# j7am_pulsar1_mem_cbass0_QOS register map
Vendor: Texas Instruments
Peripheral module from a debugger description file (folder J721S2).
Registers are 32-bit, read-write, reset 0x7000 unless marked. A register's access mark holds for its fields unless they carry their own. Offsets are as the file gives them; lines under a group give offsets from that group; [hi:lo] are bit positions; {n}, {i} and the like mark numbered series; 'fields as' and 'values as' point back to an identical list; <NAME> marks a mode.

## j7am_pulsar1_mem_cbass0_QOS
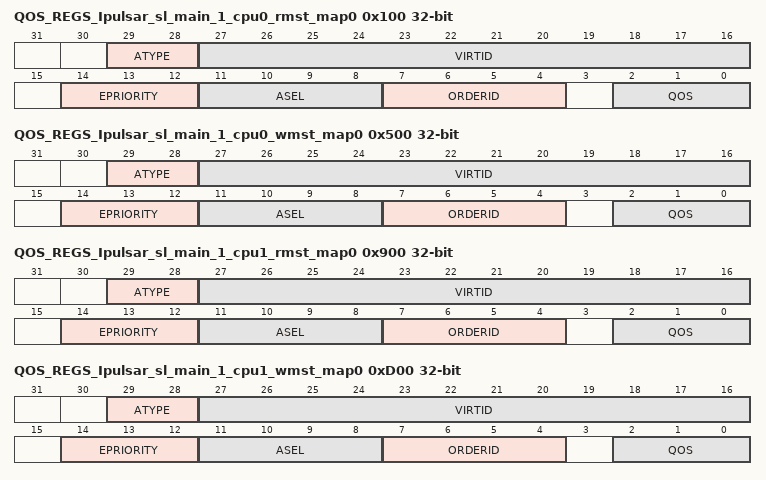
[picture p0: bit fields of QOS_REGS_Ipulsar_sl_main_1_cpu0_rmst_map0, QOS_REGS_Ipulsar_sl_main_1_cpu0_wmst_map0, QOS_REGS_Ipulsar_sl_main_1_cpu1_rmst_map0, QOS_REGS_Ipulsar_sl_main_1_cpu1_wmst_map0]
0x100 QOS_REGS_Ipulsar_sl_main_1_cpu0_rmst_map0 — The Map Register defines the fields for the master Ipulsar_sl_main_1.cpu0_rmst per channel.
  [29:28] ATYPE — epriority signal for channel N. 0 = physical. 1 = intermediate. 2 = virtual. 3 = physical with coherence.
  [27:16] VIRTID — virtid signal for channel N.
  [14:12] EPRIORITY — epriority signal for channel N.
  [11:8] ASEL — asel signal for channel N. 0 = SOC address. 1-15 = peripheral address.
  [7:4] ORDERID — orderid signal for channel N.
  [2:0] QOS — qos signal for channel N.
0x500 QOS_REGS_Ipulsar_sl_main_1_cpu0_wmst_map0 — The Map Register defines the fields for the master Ipulsar_sl_main_1.cpu0_wmst per channel.
  fields as QOS_REGS_Ipulsar_sl_main_1_cpu0_rmst_map0
0x900 QOS_REGS_Ipulsar_sl_main_1_cpu1_rmst_map0 — The Map Register defines the fields for the master Ipulsar_sl_main_1.cpu1_rmst per channel.
  fields as QOS_REGS_Ipulsar_sl_main_1_cpu0_rmst_map0
0xD00 QOS_REGS_Ipulsar_sl_main_1_cpu1_wmst_map0 — The Map Register defines the fields for the master Ipulsar_sl_main_1.cpu1_wmst per channel.
  fields as QOS_REGS_Ipulsar_sl_main_1_cpu0_rmst_map0
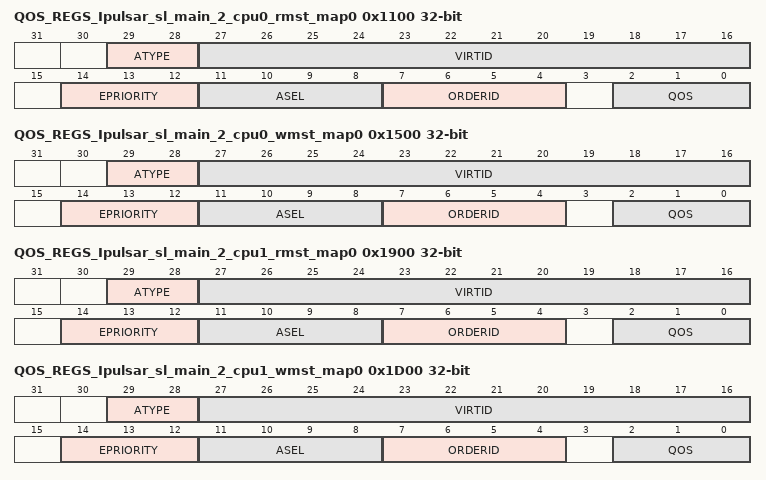
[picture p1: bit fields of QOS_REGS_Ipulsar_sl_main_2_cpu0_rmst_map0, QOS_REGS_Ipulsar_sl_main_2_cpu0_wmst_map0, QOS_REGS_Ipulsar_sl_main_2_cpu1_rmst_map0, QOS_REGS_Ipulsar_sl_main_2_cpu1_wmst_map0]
0x1100 QOS_REGS_Ipulsar_sl_main_2_cpu0_rmst_map0 — The Map Register defines the fields for the master Ipulsar_sl_main_2.cpu0_rmst per channel.
  fields as QOS_REGS_Ipulsar_sl_main_1_cpu0_rmst_map0
0x1500 QOS_REGS_Ipulsar_sl_main_2_cpu0_wmst_map0 — The Map Register defines the fields for the master Ipulsar_sl_main_2.cpu0_wmst per channel.
  fields as QOS_REGS_Ipulsar_sl_main_1_cpu0_rmst_map0
0x1900 QOS_REGS_Ipulsar_sl_main_2_cpu1_rmst_map0 — The Map Register defines the fields for the master Ipulsar_sl_main_2.cpu1_rmst per channel.
  fields as QOS_REGS_Ipulsar_sl_main_1_cpu0_rmst_map0
0x1D00 QOS_REGS_Ipulsar_sl_main_2_cpu1_wmst_map0 — The Map Register defines the fields for the master Ipulsar_sl_main_2.cpu1_wmst per channel.
  fields as QOS_REGS_Ipulsar_sl_main_1_cpu0_rmst_map0
